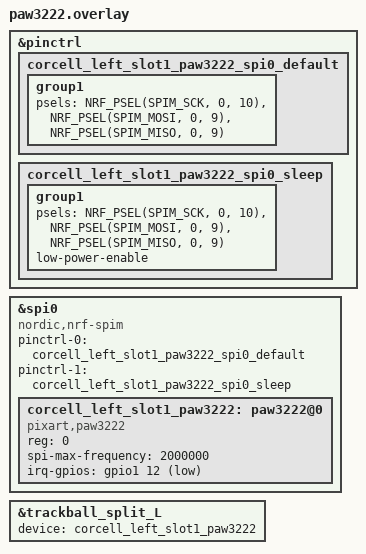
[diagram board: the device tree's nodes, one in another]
#include <dt-bindings/pinctrl/nrf-pinctrl.h>

&pinctrl {
    corcell_left_slot1_paw3222_spi0_default: corcell_left_slot1_paw3222_spi0_default {
        group1 {
            psels = <NRF_PSEL(SPIM_SCK, 0, 10)>,
                    <NRF_PSEL(SPIM_MOSI, 0, 9)>,
                    <NRF_PSEL(SPIM_MISO, 0, 9)>;
        };
    };

    corcell_left_slot1_paw3222_spi0_sleep: corcell_left_slot1_paw3222_spi0_sleep {
        group1 {
            psels = <NRF_PSEL(SPIM_SCK, 0, 10)>,
                    <NRF_PSEL(SPIM_MOSI, 0, 9)>,
                    <NRF_PSEL(SPIM_MISO, 0, 9)>;
            low-power-enable;
        };
    };
};

&spi0 {
    status = "okay";
    compatible = "nordic,nrf-spim";
    pinctrl-0 = <&corcell_left_slot1_paw3222_spi0_default>;
    pinctrl-1 = <&corcell_left_slot1_paw3222_spi0_sleep>;
    pinctrl-names = "default", "sleep";

    corcell_left_slot1_paw3222: paw3222@0 {
        compatible = "pixart,paw3222";
        reg = <0>;
        status = "okay";
        spi-max-frequency = <2000000>;
        irq-gpios = <&gpio1 12 (GPIO_ACTIVE_LOW | GPIO_PULL_UP)>;
    };
};

&trackball_split_L {
    status = "okay";
    device = <&corcell_left_slot1_paw3222>;
};
